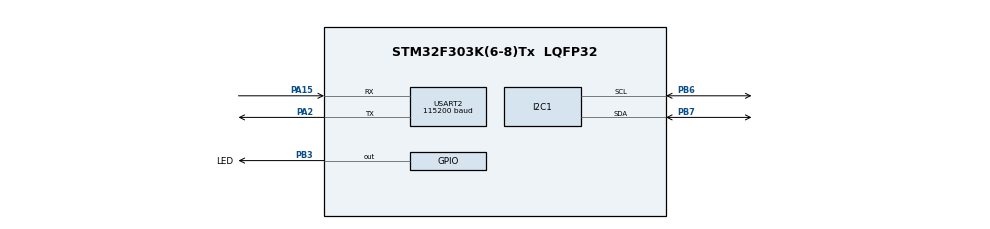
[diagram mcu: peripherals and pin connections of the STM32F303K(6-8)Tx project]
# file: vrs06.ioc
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Dma.Request0=USART2_TX
Dma.USART2_TX.0.Direction=DMA_MEMORY_TO_PERIPH
Dma.USART2_TX.0.Instance=DMA1_Channel7
Dma.USART2_TX.0.MemDataAlignment=DMA_MDATAALIGN_BYTE
Dma.USART2_TX.0.MemInc=DMA_MINC_ENABLE
Dma.USART2_TX.0.Mode=DMA_NORMAL
Dma.USART2_TX.0.PeriphDataAlignment=DMA_PDATAALIGN_BYTE
Dma.USART2_TX.0.PeriphInc=DMA_PINC_DISABLE
Dma.USART2_TX.0.Priority=DMA_PRIORITY_LOW
I2C1.Timing=0x00201D2B
Mcu.Family=STM32F3
Mcu.Name=STM32F303K(6-8)Tx
Mcu.Package=LQFP32
NVIC.DMA1_Channel7_IRQn=true\:0\:0\:false\:false\:true\:false\:true\:true
NVIC.PriorityGroup=NVIC_PRIORITYGROUP_4
PA15.Mode=Asynchronous
PA15.Signal=USART2_RX
PA2.Mode=Asynchronous
PA2.Signal=USART2_TX
PB3.GPIO_Label=LED
PB3.Signal=GPIO_Output
PB6.Mode=I2C
PB6.Signal=I2C1_SCL
PB7.Mode=I2C
PB7.Signal=I2C1_SDA
ProjectManager.HeapSize=0x200
ProjectManager.StackSize=0x400
ProjectManager.TargetToolchain=STM32CubeIDE
RCC.AHBFreq_Value=8000000
RCC.APB1Freq_Value=8000000
RCC.APB2Freq_Value=8000000
RCC.CortexFreq_Value=8000000
RCC.HSE_VALUE=8000000
RCC.HSI_VALUE=8000000
RCC.SYSCLKFreq_VALUE=8000000
USART2.BaudRate=115200
USART2.VirtualMode-Asynchronous=VM_ASYNC
board=custom

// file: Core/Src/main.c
/* USER CODE BEGIN Header */
/**
  ******************************************************************************
  * @file           : main.c
  * @brief          : Main program body (Ready-to-run for LPS22HB + HTS221)
  ******************************************************************************
  */
/* USER CODE END Header */

#include "main.h"
#include "dma.h"
#include "i2c.h"
#include "usart.h"
#include "gpio.h"

/* USER CODE BEGIN Includes */
#include "lps22hb.h"
#include "hts221.h"
#include "height_calculation.h"
#include <stdio.h>
/* USER CODE END Includes */

LPS22HB_t LPS22HB_sensor;
HTS221_t hts221_sensor;
uint16_t tx_length;
uint8_t tx_buffer[128];
float pressure_hPa = 0.0f;
float temperature_C = 0.0f;
float humidity_rh = 0.0f;

void SystemClock_Config(void);

int main(void)
{
  /* MCU Configuration--------------------------------------------------------*/
  LL_APB2_GRP1_EnableClock(LL_APB2_GRP1_PERIPH_SYSCFG);
  LL_APB1_GRP1_EnableClock(LL_APB1_GRP1_PERIPH_PWR);

  /* Configure NVIC */
  NVIC_SetPriorityGrouping(NVIC_PRIORITYGROUP_4);
  NVIC_SetPriority(SysTick_IRQn, NVIC_EncodePriority(NVIC_GetPriorityGrouping(),15, 0));

  /* Configure the system clock */
  SystemClock_Config();

  /* Initialize all configured peripherals */
  MX_GPIO_Init();
  MX_DMA_Init();
  MX_I2C1_Init();
  MX_USART2_UART_Init();

  /* Register I2C callback functions for sensor drivers (polling versions) */
  LPS22HB_RegisterIOFunctions(i2c_master_read_multi_polling,
                              i2c_master_write_multi_polling,
                              i2c_master_write_byte_polling,
                              i2c_master_read_byte_polling);

  HTS221_RegisterIOFunctions(i2c_master_read_multi_polling,
                             i2c_master_write_multi_polling,
                             i2c_master_write_byte_polling,
                             i2c_master_read_byte_polling);

  /* Initialize driver contexts */
  LPS22HB_InitDriver(&LPS22HB_sensor);
  HTS221_InitDriver(&hts221_sensor);

  /* Initialize sensors */
  if (LPS22HB_Init(&LPS22HB_sensor, 100) != LPS22HB_OK)
  {
    Error_Handler();
  }

  if (HTS221_Init(&hts221_sensor, 100) != HTS221_OK)
  {
    Error_Handler();
  }

  /* Read initial pressure to set reference for height calculation */
  if (LPS22HB_ReadPressure(&LPS22HB_sensor, &pressure_hPa, 100) == LPS22HB_OK)
  {
    Height_SetReferencePressure(pressure_hPa);
  }

  /* Infinite loop */
  while (1)
  {
    /* Read sensors */
    if (LPS22HB_ReadPressure(&LPS22HB_sensor, &pressure_hPa, 100) != LPS22HB_OK)
    {
      /* handle error (skip this cycle) */
    }

    if (HTS221_ReadTemperature(&hts221_sensor, &temperature_C, 100) != HTS221_OK)
    {
      /* handle error */
    }

    if (HTS221_ReadHumidity(&hts221_sensor, &humidity_rh, 100) != HTS221_OK)
    {
      /* handle error */
    }

    /* Format CSV: temperature [°C] "xx.x", rel. humidity [%] "xx", pressure [hPa] "xxxx.xx", relative height [m] "xxx.xx" */
    float rel_height = Height_GetRelativeHeight(pressure_hPa);
    tx_length = sprintf((char*)tx_buffer, "%.1f,%d,%.2f,%.2f\r\n",
                        temperature_C, (int)humidity_rh, pressure_hPa, rel_height);

    /* Send via USART using DMA */
    while(LL_DMA_IsEnabledChannel(DMA1, LL_DMA_CHANNEL_7)); /* wait previous */
    USART2_PutBuffer(tx_buffer, (uint8_t)tx_length);

    /* toggle heartbeat LED */
    LL_GPIO_TogglePin(GPIOB, LL_GPIO_PIN_3);

    LL_mDelay(1000);
  }
}

void SystemClock_Config(void)
{
  LL_FLASH_SetLatency(LL_FLASH_LATENCY_0);
  while(LL_FLASH_GetLatency()!= LL_FLASH_LATENCY_0) {}

  LL_RCC_HSI_Enable();
  while(LL_RCC_HSI_IsReady() != 1) {}

  LL_RCC_HSI_SetCalibTrimming(16);
  LL_RCC_SetAHBPrescaler(LL_RCC_SYSCLK_DIV_1);
  LL_RCC_SetAPB1Prescaler(LL_RCC_APB1_DIV_1);
  LL_RCC_SetAPB2Prescaler(LL_RCC_APB2_DIV_1);
  LL_RCC_SetSysClkSource(LL_RCC_SYS_CLKSOURCE_HSI);
  while(LL_RCC_GetSysClkSource() != LL_RCC_SYS_CLKSOURCE_STATUS_HSI) {}

  LL_Init1msTick(8000000);
  LL_SetSystemCoreClock(8000000);
  LL_RCC_SetI2CClockSource(LL_RCC_I2C1_CLKSOURCE_HSI);
}

void Error_Handler(void)
{
  __disable_irq();
  while (1)
  {
    LL_GPIO_TogglePin(GPIOB, LL_GPIO_PIN_3);
    LL_mDelay(200);
  }
}
